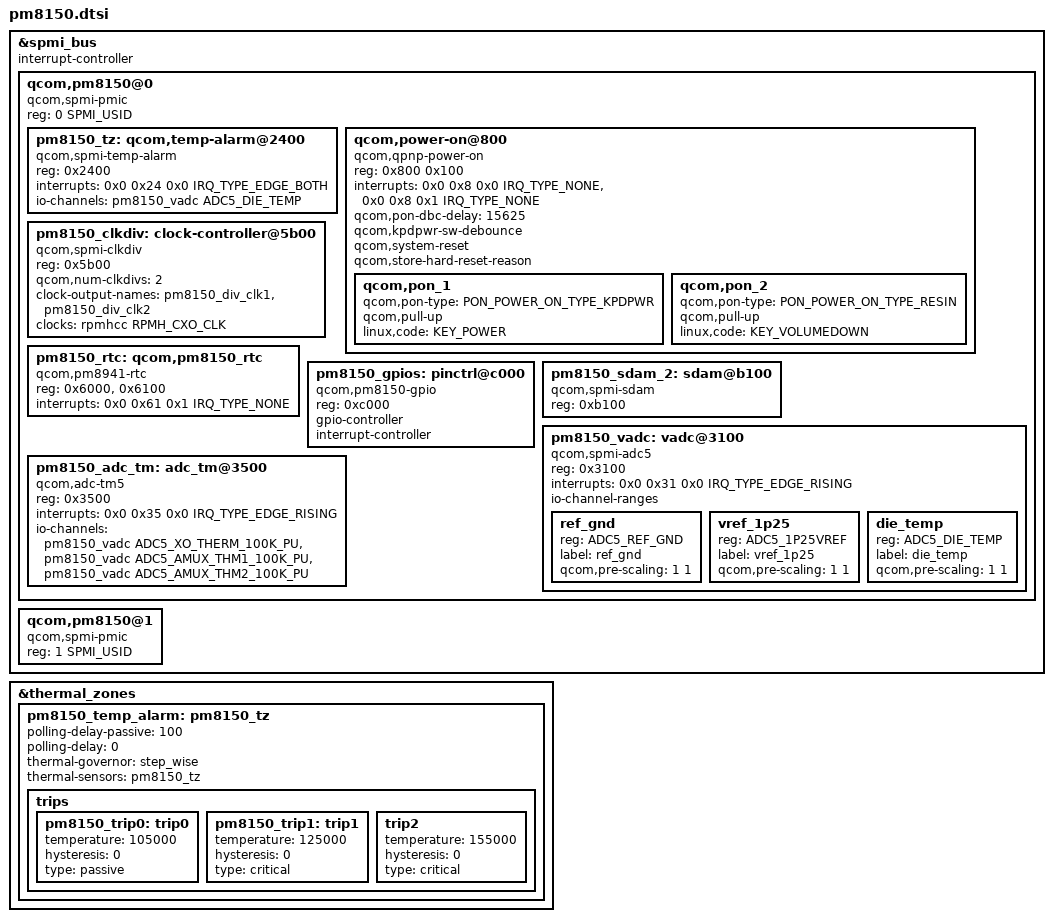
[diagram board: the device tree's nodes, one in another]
#include <dt-bindings/clock/qcom,rpmh.h>
#include <dt-bindings/iio/qcom,spmi-vadc.h>
#include <dt-bindings/input/qcom,qpnp-power-on.h>
#include <dt-bindings/interrupt-controller/irq.h>
#include <dt-bindings/spmi/spmi.h>

&spmi_bus {
	#address-cells = <2>;
	#size-cells = <0>;
	interrupt-controller;
	#interrupt-cells = <4>;

	qcom,pm8150@0 {
		compatible = "qcom,spmi-pmic";
		reg = <0 SPMI_USID>;
		#address-cells = <1>;
		#size-cells = <0>;

		pm8150_tz: qcom,temp-alarm@2400 {
			compatible = "qcom,spmi-temp-alarm";
			reg = <0x2400>;
			interrupts = <0x0 0x24 0x0 IRQ_TYPE_EDGE_BOTH>;
			io-channels = <&pm8150_vadc ADC5_DIE_TEMP>;
			io-channel-names = "thermal";
			#thermal-sensor-cells = <0>;
		};

		qcom,power-on@800 {
			compatible = "qcom,qpnp-power-on";
			reg = <0x800 0x100>;
			interrupts = <0x0 0x8 0x0 IRQ_TYPE_NONE>,
				     <0x0 0x8 0x1 IRQ_TYPE_NONE>;
			interrupt-names = "kpdpwr", "resin";
			qcom,pon-dbc-delay = <15625>;
			qcom,kpdpwr-sw-debounce;
			qcom,system-reset;
			qcom,store-hard-reset-reason;

			qcom,pon_1 {
				qcom,pon-type = <PON_POWER_ON_TYPE_KPDPWR>;
				qcom,pull-up;
				linux,code = <KEY_POWER>;
			};

			qcom,pon_2 {
				qcom,pon-type = <PON_POWER_ON_TYPE_RESIN>;
				qcom,pull-up;
				linux,code = <KEY_VOLUMEDOWN>;
			};
		};

		pm8150_clkdiv: clock-controller@5b00 {
			compatible = "qcom,spmi-clkdiv";
			reg = <0x5b00>;
			#clock-cells = <1>;
			qcom,num-clkdivs = <2>;
			clock-output-names = "pm8150_div_clk1",
						"pm8150_div_clk2";
			clocks = <&rpmhcc RPMH_CXO_CLK>;
			clock-names = "xo";
		};

		pm8150_rtc: qcom,pm8150_rtc {
			compatible = "qcom,pm8941-rtc";
			reg = <0x6000>, <0x6100>;
			reg-names = "rtc", "alarm";
			interrupts = <0x0 0x61 0x1 IRQ_TYPE_NONE>;
		};

		pm8150_gpios: pinctrl@c000 {
			compatible = "qcom,pm8150-gpio";
			reg = <0xc000>;
			gpio-controller;
			#gpio-cells = <2>;
			interrupt-controller;
			#interrupt-cells = <2>;
		};

		pm8150_sdam_2: sdam@b100 {
			compatible = "qcom,spmi-sdam";
			reg = <0xb100>;
		};

		pm8150_vadc: vadc@3100 {
			compatible = "qcom,spmi-adc5";
			reg = <0x3100>;
			#address-cells = <1>;
			#size-cells = <0>;
			interrupts = <0x0 0x31 0x0 IRQ_TYPE_EDGE_RISING>;
			interrupt-names = "eoc-int-en-set";
			#io-channel-cells = <1>;
			io-channel-ranges;

			/* Channel node */
			ref_gnd {
				reg = <ADC5_REF_GND>;
				label = "ref_gnd";
				qcom,pre-scaling = <1 1>;
			};

			vref_1p25 {
				reg = <ADC5_1P25VREF>;
				label = "vref_1p25";
				qcom,pre-scaling = <1 1>;
			};

			die_temp {
				reg = <ADC5_DIE_TEMP>;
				label = "die_temp";
				qcom,pre-scaling = <1 1>;
			};
		};

		pm8150_adc_tm: adc_tm@3500 {
			compatible = "qcom,adc-tm5";
			reg = <0x3500>;
			interrupts = <0x0 0x35 0x0 IRQ_TYPE_EDGE_RISING>;
			interrupt-names = "thr-int-en";
			#address-cells = <1>;
			#size-cells = <0>;
			#thermal-sensor-cells = <1>;
			io-channels = <&pm8150_vadc ADC5_XO_THERM_100K_PU>,
					<&pm8150_vadc ADC5_AMUX_THM1_100K_PU>,
					<&pm8150_vadc ADC5_AMUX_THM2_100K_PU>;
		};
	};

	qcom,pm8150@1 {
		compatible ="qcom,spmi-pmic";
		reg = <1 SPMI_USID>;
		#address-cells = <2>;
		#size-cells = <0>;
	};
};

&thermal_zones {
	pm8150_temp_alarm: pm8150_tz {
		polling-delay-passive = <100>;
		polling-delay = <0>;
		thermal-governor = "step_wise";
		thermal-sensors = <&pm8150_tz>;

		trips {
			pm8150_trip0: trip0 {
				temperature = <105000>;
				hysteresis = <0>;
				type = "passive";
			};

			pm8150_trip1: trip1 {
				temperature = <125000>;
				hysteresis = <0>;
				type = "critical";
			};

			trip2 {
				temperature = <155000>;
				hysteresis = <0>;
				type = "critical";
			};
		};
	};
};
